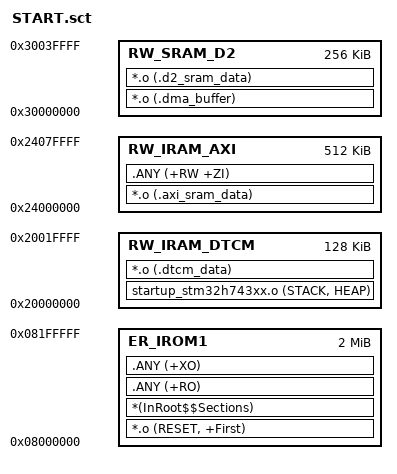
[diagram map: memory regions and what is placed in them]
; STM32H743 AC5 Scatter File
; Permanent memory layout
; - DTCM: stack/heap + latency-critical CPU-only data (.dtcm_data)
; - AXI SRAM: default RW/ZI pool + explicit large buffers (.axi_sram_data)
; - D2 SRAM: explicit DMA / dedicated sections only (.dma_buffer, .d2_sram_data)
; - SDRAM fixed windows used outside the linker:
;   * 0xC0000000..0xC06FFFFF reserved by LTDC/camera/display fixed buffers
;   * 0xC0700000..0xC07BFFFF reserved by the LVGL full-screen panel framebuffer
;   * 0xC07C0000..0xC07CBFFF reserved by the LVGL heap pool

LR_IROM1 0x08000000 0x00200000  {
  ER_IROM1 0x08000000 0x00200000  {
   *.o (RESET, +First)
   *(InRoot$$Sections)
   .ANY (+RO)
   .ANY (+XO)
  }

  RW_IRAM_DTCM 0x20000000 0x00020000  {
   startup_stm32h743xx.o (STACK, HEAP)
   *.o (.dtcm_data)
  }

  RW_IRAM_AXI 0x24000000 0x00080000  {
   *.o (.axi_sram_data)
   .ANY (+RW +ZI)
  }

  RW_SRAM_D2 0x30000000 0x00040000  {
   *.o (.dma_buffer)
   *.o (.d2_sram_data)
  }

}
